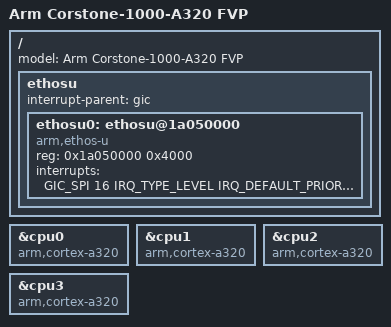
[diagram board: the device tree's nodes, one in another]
/*
 * Copyright (c) 2026 BayLibre SAS
 * SPDX-License-Identifier: Apache-2.0
 */

/dts-v1/;

#include <arm64/armv9-a.dtsi>
#include "fvp_corstone1000.dtsi"

/ {
	model = "Arm Corstone-1000-A320 FVP";

	ethosu {
		#address-cells = <1>;
		#size-cells = <1>;
		interrupt-parent = <&gic>;

		ethosu0: ethosu@1a050000 {
			compatible = "arm,ethos-u";
			reg = <0x1a050000 0x4000>;
			interrupts = <GIC_SPI 16 IRQ_TYPE_LEVEL
				      IRQ_DEFAULT_PRIORITY>;
			status = "okay";
		};
	};
};

&cpu0 {
	compatible = "arm,cortex-a320";
};

&cpu1 {
	compatible = "arm,cortex-a320";
};

&cpu2 {
	compatible = "arm,cortex-a320";
};

&cpu3 {
	compatible = "arm,cortex-a320";
};
